# f28p65x_clk_cfg_regs register map
Vendor: Texas Instruments
Peripheral module from a debugger description file (folder C2000).
Address unit: 16 bits
Registers are 32-bit, read-write, no defined reset value unless marked. A register's access mark holds for its fields unless they carry their own. Offsets are as the file gives them; lines under a group give offsets from that group; [hi:lo] are bit positions; {n}, {i} and the like mark numbered series; 'fields as' and 'values as' point back to an identical list; <NAME> marks a mode.

## CLK_CFG_REGS — CLK CFG Registers
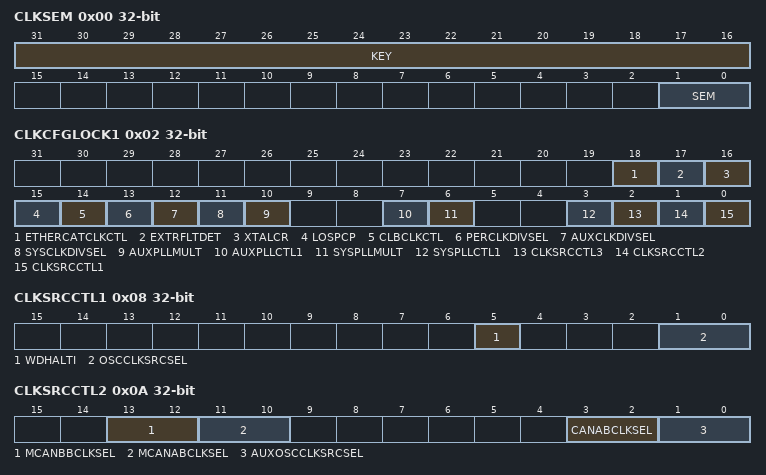
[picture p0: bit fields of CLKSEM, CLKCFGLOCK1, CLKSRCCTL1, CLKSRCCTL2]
0x00 CLKSEM — Clock Control Semaphore Register
  [31:16] KEY — Key Qualifier for writes to this register
  [1:0] SEM — Semaphore for CLKCFG Ownership by CPU1 or CPU2
0x02 CLKCFGLOCK1 — Lock bit for CLKCFG registers
  [18] ETHERCATCLKCTL — Lockbit for ETHERCATCLKCTL register
  [17] EXTRFLTDET — Lockbit for EXTRFLTDET register
  [16] XTALCR — Lock bit for XTALCR and XTALCR2 register
  [15] LOSPCP — Lock bit for LOSPCP register
  [14] CLBCLKCTL — Lock bit for CLBCLKCTL register
  [13] PERCLKDIVSEL — Lock bit for PERCLKDIVSEL register
  [12] AUXCLKDIVSEL — Lock bit for AUXCLKDIVSEL register
  [11] SYSCLKDIVSEL — Lock bit for SYSCLKDIVSEL register
  [10] AUXPLLMULT — Lock bit for AUXPLLMULT register
  [7] AUXPLLCTL1 — Lock bit for AUXPLLCTL1 register
  [6] SYSPLLMULT — Lock bit for SYSPLLMULT register
  [3] SYSPLLCTL1 — Lock bit for SYSPLLCTL1 register
  [2] CLKSRCCTL3 — Lock bit for CLKSRCCTL3 register
  [1] CLKSRCCTL2 — Lock bit for CLKSRCCTL2 register
  [0] CLKSRCCTL1 — Lock bit for CLKSRCCTL1 register
0x08 CLKSRCCTL1 — Clock Source Control register-1
  [5] WDHALTI — Watchdog HALT Mode Ignore Bit
  [1:0] OSCCLKSRCSEL — OSCCLK Source Select Bit
0x0A CLKSRCCTL2 — Clock Source Control register-2
  [13:12] MCANBBCLKSEL — MCANB Bit Clock Source Select Bit
  [11:10] MCANABCLKSEL — MCANA Bit Clock Source Select Bit
  [3:2] CANABCLKSEL — CANA Bit Clock Source Select Bit
  [1:0] AUXOSCCLKSRCSEL — AUXOSCCLK Source Select Bit
0x0C CLKSRCCTL3 — Clock Source Control register-3
  [3:0] XCLKOUTSEL — XCLKOUT Source Select Bit
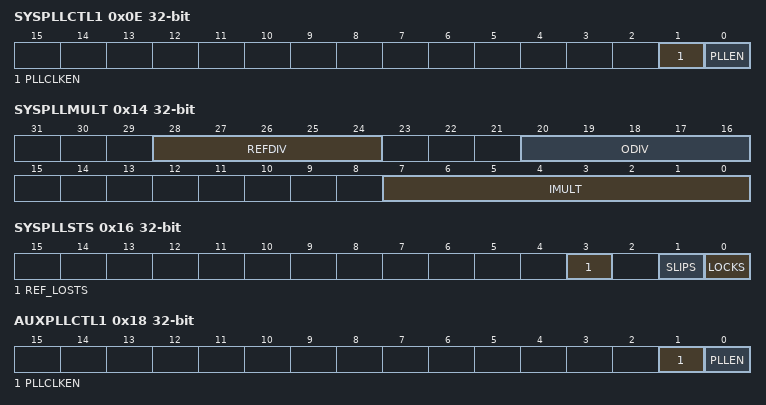
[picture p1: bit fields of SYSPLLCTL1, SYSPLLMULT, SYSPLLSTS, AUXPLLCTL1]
0x0E SYSPLLCTL1 — SYSPLL Control register-1
  [1] PLLCLKEN — SYSPLL bypassed or included in the PLLSYSCLK path
  [0] PLLEN — SYSPLL enable/disable bit
0x14 SYSPLLMULT — SYSPLL Multiplier register
  [28:24] REFDIV — Reference Clock Divider
  [20:16] ODIV — Output Clock Divider
  [7:0] IMULT — SYSPLL Integer Multiplier
0x16 SYSPLLSTS access per field — SYSPLL Status register
  [3] REF_LOSTS rw — SYSPLL Reference Lost Status Bit
  [1] SLIPS ro — SYSPLL Slip Status Bit
  [0] LOCKS ro — SYSPLL Lock Status Bit
0x18 AUXPLLCTL1 — AUXPLL Control register-1
  [1] PLLCLKEN — AUXPLL bypassed or included in the AUXPLLCLK path
  [0] PLLEN — AUXPLL enable/disable bit
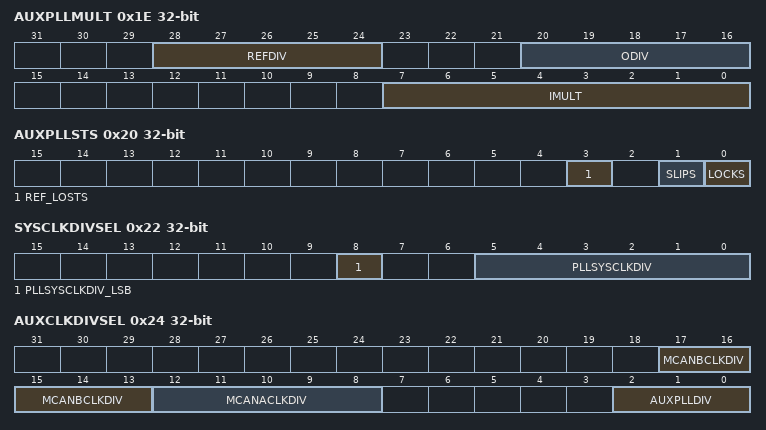
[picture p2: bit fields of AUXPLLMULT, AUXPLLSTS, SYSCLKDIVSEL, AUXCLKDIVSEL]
0x1E AUXPLLMULT — AUXPLL Multiplier register
  [28:24] REFDIV — Reference Clock Divider
  [20:16] ODIV — Output Clock Divider
  [7:0] IMULT — AUXPLL Integer Multiplier
0x20 AUXPLLSTS ro — AUXPLL Status register
  [3] REF_LOSTS — AUXPLL Reference Lost Status Bit
  [1] SLIPS — AUXPLL Slip Status Bit
  [0] LOCKS — AUXPLL Lock Status Bit
0x22 SYSCLKDIVSEL — System Clock Divider Select register
  [8] PLLSYSCLKDIV_LSB — PLLSYSCLKDIV_LSB Select
  [5:0] PLLSYSCLKDIV — PLLSYSCLK Divide Select
0x24 AUXCLKDIVSEL — Auxillary Clock Divider Select register
  [17:13] MCANBCLKDIV — Divider CANFD Bit CLK for MCANB
  [12:8] MCANACLKDIV — Divider CANFD Bit CLK for MCANA
  [2:0] AUXPLLDIV — AUXPLLCLK Divide Select
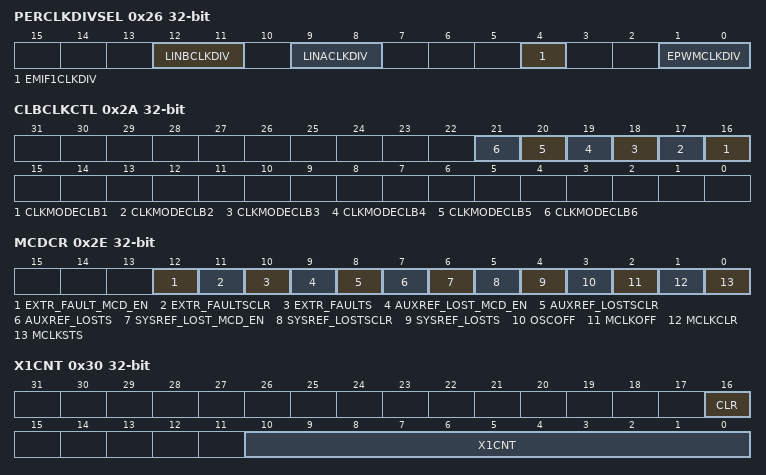
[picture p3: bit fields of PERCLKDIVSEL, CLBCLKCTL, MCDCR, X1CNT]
0x26 PERCLKDIVSEL — Peripheral Clock Divider Select register
  [12:11] LINBCLKDIV — LINB Clock Divide Select
  [9:8] LINACLKDIV — LINA Clock Divide Select
  [4] EMIF1CLKDIV — EMIF1 Clock Divide Select
  [1:0] EPWMCLKDIV — EPWM Clock Divide Select
0x28 XCLKOUTDIVSEL — XCLKOUT Divider Select register
  [1:0] XCLKOUTDIV — XCLKOUT Divide Select
0x2A CLBCLKCTL — CLB Clocking Control Register
  [n+15] CLKMODECLB{n} (n=1..6) — Clock mode of CLB{n}
0x2C LOSPCP — Low Speed Clock Source Prescalar
  [2:0] LSPCLKDIV — LSPCLK Divide Select
0x2E MCDCR access per field — Missing Clock Detect Control Register
  [12] EXTR_FAULT_MCD_EN rw — Configuration to enable EXTR_FAULTS as MCD cause
  [11] EXTR_FAULTSCLR rw — External Resistor fault status clear
  [10] EXTR_FAULTS ro — External Resistor fault indication
  [9] AUXREF_LOST_MCD_EN rw — Enable for PLL REF_CLK_LOST as MCD cause
  [8] AUXREF_LOSTSCLR rw — Clear for Ref clock lost status
  [7] AUXREF_LOSTS ro — AUXPLL Reference Lost Status Bit
  [6] SYSREF_LOST_MCD_EN rw — Enable for PLL REF_CLK_LOST as MCD cause
  [5] SYSREF_LOSTSCLR rw — Clear for Ref clock lost status
  [4] SYSREF_LOSTS ro — SYSPLL Reference Lost Status Bit
  [3] OSCOFF rw — Oscillator Clock Off Bit
  [2] MCLKOFF rw — Missing Clock Detect Off Bit
  [1] MCLKCLR rw — Missing Clock Clear Bit
  [0] MCLKSTS ro — Missing Clock Status Bit
0x30 X1CNT access per field — 10-bit Counter on X1 Clock
  [16] CLR rw — X1 Counter Clear
  [10:0] X1CNT ro — X1 Counter
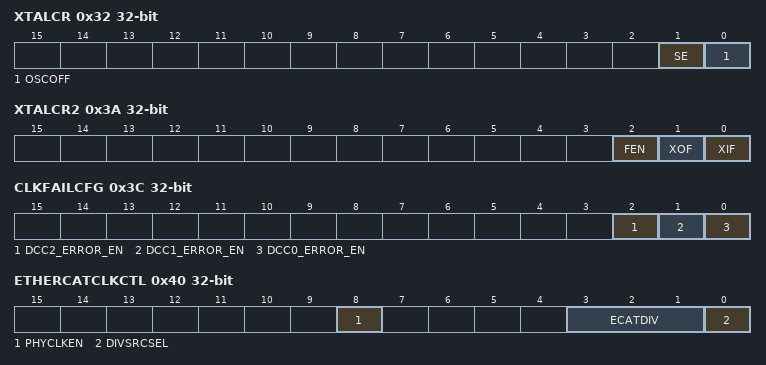
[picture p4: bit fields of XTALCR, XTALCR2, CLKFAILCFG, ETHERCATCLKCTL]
0x32 XTALCR — XTAL Control Register
  [1] SE — XTAL Oscilator in Single-Ended mode
  [0] OSCOFF — XTAL Oscillator powered-down
0x3A XTALCR2 — XTAL Control Register for pad init
  [2] FEN — XOSC pads initialisation enable
  [1] XOF — XO Initial value deposited before XOSC start
  [0] XIF — XI Initial value deposited before XOSC start
0x3C CLKFAILCFG — Clock Fail cause Configuration
  [2] DCC2_ERROR_EN — DCC2 Error causes Clock fail NMI, ERROR
  [1] DCC1_ERROR_EN — DCC1 Error causes Clock fail NMI, ERROR
  [0] DCC0_ERROR_EN — DCC0 Error causes Clock fail NMI, ERROR
0x40 ETHERCATCLKCTL — EtherCAT Clock Control
  [8] PHYCLKEN — etherCAT PHY clock enable
  [3:1] ECATDIV — etherCAT clock divider configuration.
  [0] DIVSRCSEL — Clock source select for the etherCAT clock divider.
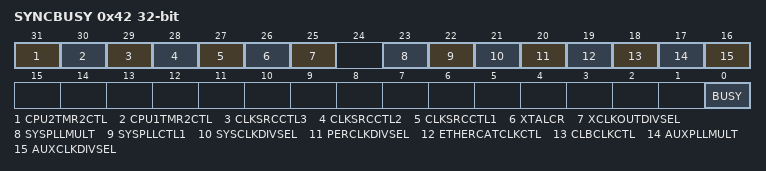
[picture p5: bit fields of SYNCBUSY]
0x42 SYNCBUSY ro — Pulse Transfer Sync Busy Status register
  [31] CPU2TMR2CTL — BUSY status bit for CPU2TMR2CTL
  [30] CPU1TMR2CTL — BUSY status bit for CPU1TMR2CTL
  [29] CLKSRCCTL3 — BUSY status bit for CLKSRCCTL3
  [28] CLKSRCCTL2 — BUSY status bit for CLKSRCCTL2
  [27] CLKSRCCTL1 — BUSY status bit for CLKSRCCTL1
  [26] XTALCR — BUSY status bit for XTALCR
  [25] XCLKOUTDIVSEL — BUSY status bit for XCLKOUTDIVSEL
  [23] SYSPLLMULT — BUSY status bit for SYSPLLMULT
  [22] SYSPLLCTL1 — BUSY status bit for SYSPLLCTL1
  [21] SYSCLKDIVSEL — BUSY status bit for SYSCLKDIVSEL
  [20] PERCLKDIVSEL — BUSY status bit for PERCLKDIVSEL
  [19] ETHERCATCLKCTL — BUSY status bit for ETHERCATCLKCTL
  [18] CLBCLKCTL — BUSY status bit for CLBCLKCTL
  [17] AUXPLLMULT — BUSY status bit for AUXPLLMULT
  [16] AUXCLKDIVSEL — BUSY status bit for AUXCLKDIVSEL
  [0] BUSY — Status bit indicating synchronization in progress
